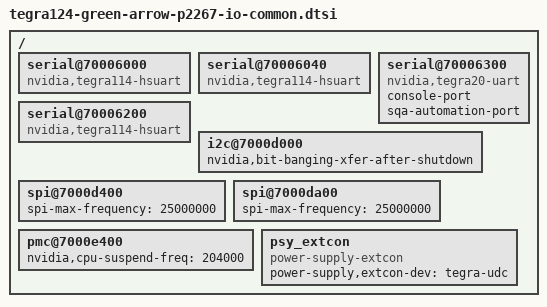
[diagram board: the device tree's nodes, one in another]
/*
 * tegra124-green-arrow-p2267-io-common.dtsi: Common IO file for Green Arrow
 *
 * Copyright (c) 2015, NVIDIA CORPORATION.  All rights reserved.
 *
 * This program is free software; you can redistribute it and/or modify
 * it under the terms of the GNU General Public License as published by
 * the Free Software Foundation; either version 2 of the License, or
 * (at your option) any later version.
 *
 * This program is distributed in the hope that it will be useful, but WITHOUT
 * ANY WARRANTY; without even the implied warranty of MERCHANTABILITY or
 * FITNESS FOR A PARTICULAR PURPOSE.  See the GNU General Public License for
 * more details.
 */

/* This file is mainly for IO-Peripherals like SPI/I2C/USB/UART etc */

/ {
	serial@70006000 {
		compatible = "nvidia,tegra114-hsuart";
		status = "okay";
	};

	serial@70006040 {
		compatible = "nvidia,tegra114-hsuart";
		status = "okay";
	};

	serial@70006200 {
		compatible = "nvidia,tegra114-hsuart";
		status = "okay";
	};

	serial@70006300 {
		compatible = "nvidia,tegra20-uart", "nvidia,tegra114-hsuart";
		console-port;
		sqa-automation-port;
		status = "okay";
	};

	i2c@7000d000 {
		nvidia,bit-banging-xfer-after-shutdown;
	};

	spi@7000d400 {
		status = "okay";
		spi-max-frequency = <25000000>;
	};

	spi@7000da00 {
		status = "okay";
		spi-max-frequency = <25000000>;
	};

	pmc@7000e400 {
		status = "okay";
		nvidia,cpu-suspend-freq = <204000>;
	};

	psy_extcon {
		compatible = "power-supply-extcon";
		power-supply,extcon-dev = "tegra-udc";
	};
};
